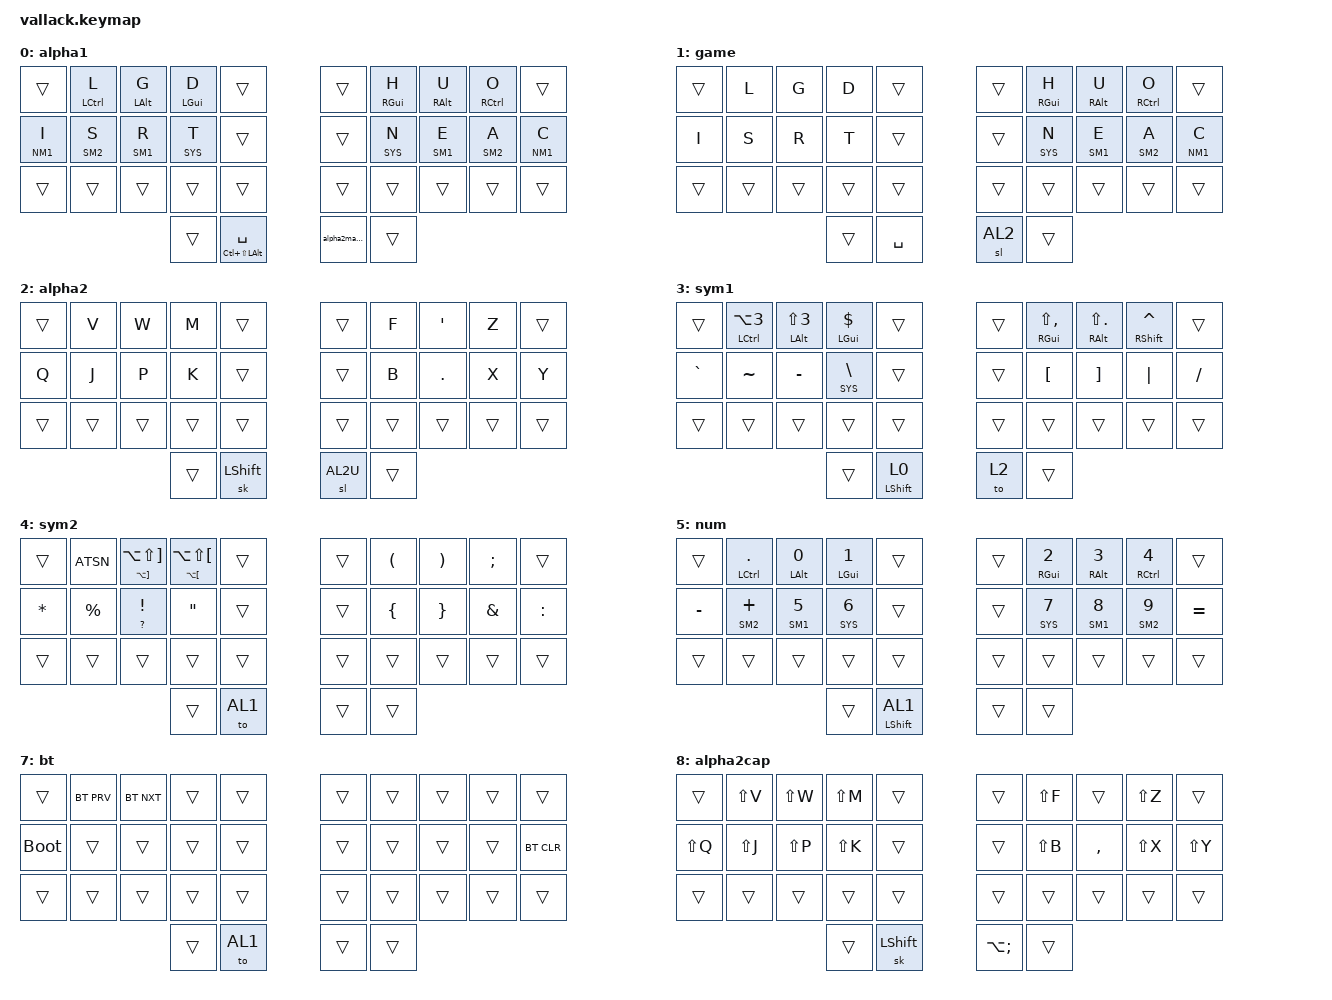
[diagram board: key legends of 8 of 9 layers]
/*
 * Copyright (c) 2020 The ZMK Contributors
 *
 * SPDX-License-Identifier: MIT
 */

#include <behaviors.dtsi>
#include <dt-bindings/zmk/keys.h>
#include <dt-bindings/zmk/bt.h>


&mt {
    tapping-term-ms = <201>;
    flavor = "tap-preferred";
 };
&sk {
     release-after-ms = <2000>;
     quick-release;
 };
 
/* Layers */
#define AL1 0
#define GM 1
#define AL2 2
#define AL2U 8
#define SM1 3
#define SM2 4	
#define NM1 5	
#define SYS 6
#define BT 7	
/ { 
    combos {
        compatible = "zmk,combos";
        combo_game {
            timeout-ms = <30>;
	    key-positions = <2 3 6 7>;
            bindings = <&to GM>;
        };
        combo_sys {
            timeout-ms = <30>;
	    key-positions = <6 7 8>;
            bindings = <&to SYS>;
        };
        combo_caps {
            timeout-ms = <30>;
	    key-positions = <16 17 18>;
            bindings = <&caps_word>;
        };
        combo_bt  {
            timeout-ms = <10>;
            key-positions = <17 18>;
            bindings = <&to BT>;
	    layers = <SM1>; 
        };
        lalt {
            timeout-ms = <20>;
	    key-positions = <12 13>;
            bindings = <&kp LALT>; 
	    layers = <SYS>; 
        };
        lclk {
            timeout-ms = <20>;
	    key-positions = <13 16>;
            bindings = <&kp LC(LS(LA(N1)))>;
	    layers = <SYS>;
        };
        rclk {
            timeout-ms = <20>;
	    key-positions = <6 7>;
            bindings = <&kp LC(LS(LA(N2)))>;
	    layers = <SYS>;
        };


    };

    behaviors {
        hm: homerow_mods {
            compatible = "zmk,behavior-hold-tap";
            label = "HOMEROW_MODS";
            #binding-cells = <2>;
            tapping-term-ms = <300>;
            quick_tap_ms = <0>;
            flavor = "tap-preferred";
            bindings = <&kp>, <&kp>;
        };
        sr: shift_layer {
            compatible = "zmk,behavior-hold-tap";
            label = "SHIFT_LAYER";
            #binding-cells = <2>;
            tapping-term-ms = <300>;
            quick_tap_ms = <0>;
            flavor = "tap-preferred";
            bindings = <&kp>, <&to>;
	    retro-tap;
        };
        hl: homerow_layers {
            compatible = "zmk,behavior-hold-tap";
            label = "HOMEROW_LAYERS";
            #binding-cells = <2>;
            tapping-term-ms = <200>;
            quick_tap_ms = <0>;
            flavor = "tap-preferred";
            bindings = <&sl>, <&kp>;
        };
	td: tapdance {
            compatible = "zmk,behavior-hold-tap";
            label = "TAPDANCE";
            #binding-cells = <2>;
            tapping-term-ms = <190>;
            quick_tap_ms = <0>;
            flavor = "tap-preferred";
            bindings = <&kp>, <&kp>;
        };
alpha2macro: behavior_macro_1 {
		compatible = "zmk,behavior-macro";
		label = "MACRO1";
		#binding-cells = <0>;
		bindings = < &sl AL2 >;
	};
    };
       keymap {
                compatible = "zmk,keymap";

          alpha1 {
            bindings = <
              &trans 		&hm LCTL L 	&hm LALT G 	&hm LGUI D    &trans          &trans    &hm RGUI H 	&hm RALT U    		&hm RCTL O	&trans
              &hl NM1 I	&hl SM2 S	&hl SM1 R	&hl SYS T    &trans          &trans    &hl SYS N    	&hl SM1 E   		&hl SM2 A 	&hl NM1 C
              &trans    &trans    &trans    &trans    &trans          &trans    &trans    &trans    &trans    &trans
                                            &trans    &mt LC(LS(LALT)) SPC 	&alpha2macro    &trans
            >;
          };

          game {
            bindings = <
              &trans 		&kp L 		&kp G 		&kp D	    &trans          &trans    &hm RGUI H 	&hm RALT U    		&hm RCTL O	&trans
              &kp I		&kp S		&kp R		&kp T    &trans          &trans    &hl SYS N    	&hl SM1 E   		&hl SM2  A 	&hl NM1 C
              &trans    &trans    &trans    &trans    &trans          &trans    &trans    &trans    &trans    &trans
                                            &trans    &kp SPC 		&sl AL2    &trans
            >;
          };
       	  alpha2 {
            bindings = <
              &trans 	 	&kp V 		&kp W		&kp M    &trans         &trans &kp F    	&kp SQT		&kp Z 		&trans
              &kp Q	 	&kp J 		&kp P		&kp K    &trans          &trans    &kp B 		&kp DOT		&kp X		&kp Y
              &trans    &trans    &trans    &trans    &trans          &trans    &trans    &trans    &trans    &trans
                                            &trans    &sk LSHIFT 		&sl AL2U    &trans
            >;
          };
         sym1 {
            bindings = <
              &trans 		&hm LCTL LA(N3)   	&hm LALT LS(N3) 		&hm LGUI DLLR    &trans          &trans    &hm RGUI LS(COMMA)	&hm RALT LS(DOT)	&hm RSHIFT CARET	&trans
              &kp GRAVE	&kp TILDE  		&kp MINUS	      		&hl SYS BSLH    &trans          &trans    &kp LBKT		&kp RBKT	 	&kp PIPE	 	&kp SLASH
              &trans    &trans    &trans    &trans    &trans          &trans    &trans    &trans    &trans    &trans
                                            &trans    &sr LSHIFT 0 		&to 2    &trans
            >;
          };
	     sym2 {
            bindings = <
              &trans		&kp ATSN	&td LA(RBKT) LA(LS(RBKT))	&td  LA(LBKT) LA(LS(LBKT))    &trans          &trans    &kp LPRN	&kp RPRN 	&kp SEMI 	&trans
              &kp STAR  	&kp PRCNT	&td QMARK EXCL       		&kp DQT    &trans          &trans    &kp LBRC  	&kp RBRC	&kp AMPS	&kp COLON
              &trans    &trans    &trans    &trans    &trans          &trans    &trans    &trans    &trans    &trans
                                            &trans    &to AL1         &trans    &trans
            >;
          };	

        num {
            bindings = <
              &trans		&hm LCTL DOT 	&hm LALT N0	&hm LGUI N1    &trans          &trans    &hm RGUI N2 	&hm RALT N3	&hm RCTL N4	&trans
              &kp MINUS	&hl SM2 PLUS 	&hl SM1 N5	&hl SYS N6    &trans          &trans    &hl SYS N7	&hl SM1 N8	&hl SM2 N9   	&kp EQUAL
              &trans    &trans    &trans    &trans    &trans          &trans    &trans    &trans    &trans    &trans
                                            &trans    &sr LSHIFT AL1          &trans    &trans
            >;
          };
        sys {
          bindings = <
            &trans		 	&kp ESC		&kp LC(LS(TAB)) 	&kp  RC(TAB)    &trans          &trans    &td LG(V) LG(C) 	&kp UP 		&td Q BKSP 			&trans
            &td LG(GRAVE) TAB	&td HOME DEL	&td END LG(LBKT) 	&kp LG(RBKT)    &trans          &trans    &td TAB LEFT  		&kp DOWN 	&td  LC(LG(LS(N4))) RIGHT 	&kp RET
            &trans    &trans    &trans    &trans    &trans    &trans          &trans    &trans    &trans    &trans    &trans
                                          &trans    &sr LSHIFT AL1 		&kp RGUI    &trans
          >;
        };

          bt {
            bindings = <
              &trans		&bt BT_PRV	&bt BT_NXT	&trans    &trans          &trans    &trans    &trans    &trans    &trans
              &bootloader  	&trans 		&trans 		&trans    &trans          &trans    &trans 	&trans 	&trans	&bt BT_CLR
              &trans    &trans    &trans    &trans    &trans          &trans    &trans    &trans    &trans    &trans
                                            &trans    &to AL1          &trans    &trans
            >;
          };
          alpha2cap {
            bindings = <
              &trans 	 	&kp LS(V)	&kp LS(W)	&kp LS(M)    &trans          &trans    &kp LS(F)    	&trans		&kp LS(Z)	&trans
              &kp LS(Q) 	&kp LS(J) 	&kp LS(P)	&kp LS(K)    &trans          &trans    &kp LS(B)	&kp COMMA	&kp LS(X)	&kp LS(Y)
              &trans    &trans    &trans    &trans    &trans          &trans    &trans    &trans    &trans    &trans
                                            &trans    &sk LSHIFT          &kp LA(SEMI)    &trans
            >;
          };
        
	};
      //  empty_layer {
      //      bindings = <
      //        &trans    &trans    &trans    &trans    &trans          &trans    &trans    &trans    &trans    &trans
      //        &trans    &trans    &trans    &trans    &trans          &trans    &trans    &trans    &trans    &trans
      //        &trans    &trans    &trans    &trans    &trans          &trans    &trans    &trans    &trans    &trans
      //                                      &trans    &trans          &trans    &trans
      //      >;
      //    };     
};
